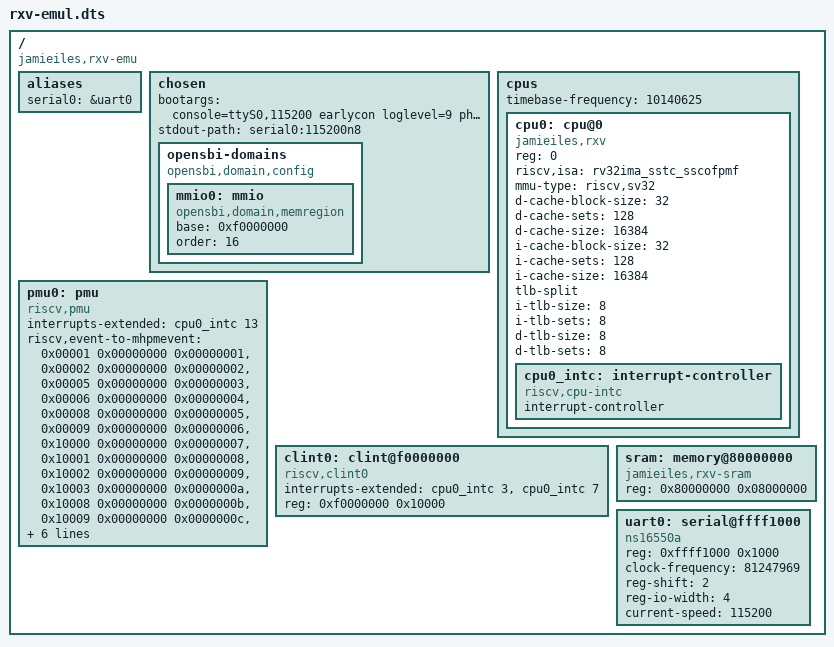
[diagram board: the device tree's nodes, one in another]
// SPDX-License-Identifier: GPL-2.0+
/dts-v1/;

/ {
    #address-cells = <1>;
    #size-cells = <1>;
    compatible = "jamieiles,rxv-emu";

    aliases {
        serial0 = &uart0;
    };

    chosen {
        bootargs = "console=ttyS0,115200 earlycon loglevel=9 phram.phram=rootfs,0x88000000,96Mi root=/dev/mtdblock0 rw init=/bin/bash";
        stdout-path = "serial0:115200n8";

        opensbi-domains {
            compatible = "opensbi,domain,config";

            mmio0: mmio {
                compatible = "opensbi,domain,memregion";
                base = <0xf0000000>;
                order = <16>;
            };
        };
    };

    cpus {
        #address-cells = <1>;
        #size-cells = <0>;
        // timebase-frequency = <100000000>;
        timebase-frequency = <10140625>;

        cpu0: cpu@0 {
            device_type = "cpu";
            compatible = "jamieiles,rxv", "riscv";
            reg = <0>;
            riscv,isa = "rv32ima_sstc_sscofpmf";
            mmu-type = "riscv,sv32";
            d-cache-block-size = <32>;
            d-cache-sets = <128>;
            d-cache-size = <16384>;
            i-cache-block-size = <32>;
            i-cache-sets = <128>;
            i-cache-size = <16384>;
            tlb-split;
            i-tlb-size = <8>;
            i-tlb-sets = <8>;
            d-tlb-size = <8>;
            d-tlb-sets = <8>;

            cpu0_intc: interrupt-controller {
                #interrupt-cells = <1>;
                #address-cells = <0>;
                interrupt-controller;
                compatible = "riscv,cpu-intc";
            };
        };
    };

    pmu0: pmu {
        compatible = "riscv,pmu";
        interrupts-extended = <&cpu0_intc 13>;
        riscv,event-to-mhpmevent = <0x00001 0x00000000 0x00000001> /* Cycles */,
                                   <0x00002 0x00000000 0x00000002> /* Instructions Retired */,
                                   <0x00005 0x00000000 0x00000003> /* Branches */,
                                   <0x00006 0x00000000 0x00000004> /* Branch Mispredict */,
                                   <0x00008 0x00000000 0x00000005> /* Frontend Stall */,
                                   <0x00009 0x00000000 0x00000006> /* Backend Stall */,
                                   <0x10000 0x00000000 0x00000007> /* L1D Read */,
                                   <0x10001 0x00000000 0x00000008> /* L1D Read Miss */,
                                   <0x10002 0x00000000 0x00000009> /* L1D Write */,
                                   <0x10003 0x00000000 0x0000000a> /* L1D Write Miss */,
                                   <0x10008 0x00000000 0x0000000b> /* L1I Read */,
                                   <0x10009 0x00000000 0x0000000c> /* L1I Read Miss */,
                                   <0x10018 0x00000000 0x0000000d> /* DTLB Read */,
                                   <0x10019 0x00000000 0x0000000e> /* DTLB Read Miss */,
                                   <0x10020 0x00000000 0x0000000f> /* ITLB Read */,
                                   <0x10021 0x00000000 0x00000010> /* ITLB Read Miss */;
        riscv,event-to-mhpmcounters = <0x00001 0x10181 0x00000078>;
    };

    clint0: clint@f0000000 {
        compatible = "riscv,clint0";
        interrupts-extended = <&cpu0_intc 3 &cpu0_intc 7 >;
        reg = <0xf0000000 0x10000>;
    };

    sram: memory@80000000 {
        device_type = "memory";
        compatible = "jamieiles,rxv-sram";
        reg = <0x80000000 0x08000000>;
    };

    uart0: serial@ffff1000 {
        compatible = "ns16550a";
        reg = <0xffff1000 0x1000>;
        clock-frequency = <81247969>;
        reg-shift = <2>;
        reg-io-width = <4>;
        status = "okay";
        current-speed = <115200>;
    };
};
